# MIK32 register map
Vendor: Mikron; Series: MIK32; File version: 1.0
Registers are 32-bit, read-write, reset 0x0 unless marked. A register's access mark holds for its fields unless they carry their own. Offsets are from the block's base; [hi:lo] are bit positions.

## DAC0 — Управление ЦАП
Base 0x00085000
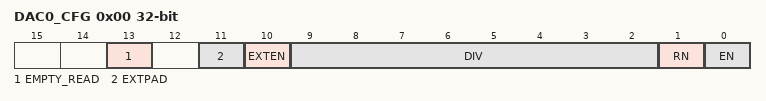
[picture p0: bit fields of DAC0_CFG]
0x00 DAC0_CFG — Регистр настойки ЦАП0
  [13] EMPTY_READ ro — Состояние входного регистра DAC_VALUE. Сбрасывается в 0 при записи нового значения в DAC_VALUE.
    0=Full (В DAC_VALUE находится необработанное значение); 1=Empty (Значение из DAC_VALUE передано в ЦАП, возможна запись следующего значения)
  [11] EXTPAD — Выбор источника внешнего опорного напряжения
    0=Calibrated_voltage_reference (Настраиваемый ИОН); 1=REF_DAC_PIN (Внешний вывод REF_ADC_DAC (PORT1_11))
  [10] EXTEN — Выбор источника опорного напряжения
    0=Internal (Встроенный); 1=External (Внешний)
  [9:2] DIV — Значение делителя тактового сигнала. Частота определяется как FЦАП=FIN/(DIV+1)
  [1] RN — Управление сбросом ЦАП, активный уровень «0»
  [0] EN — Управление питанием ЦАП
    0=Disable (Выключен); 1=Enable (Включен)
0x04 DAC0_VALUE — Входные данные для ЦАП0
  [11:0] VALUE — 12-разрядный входной код ЦАП

## DAC1 — Управление ЦАП
Base 0x00085008
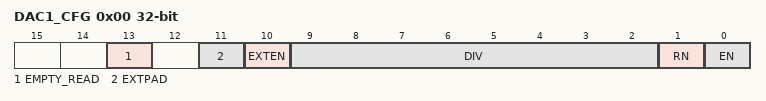
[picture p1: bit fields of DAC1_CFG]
0x00 DAC1_CFG — Регистр настойки ЦАП1
  [13] EMPTY_READ ro — Состояние входного регистра DAC_VALUE. Сбрасывается в 0 при записи нового значения в DAC_VALUE.
    0=Full (В DAC_VALUE находится необработанное значение); 1=Empty (Значение из DAC_VALUE передано в ЦАП, возможна запись следующего значения)
  [11] EXTPAD — Выбор источника внешнего опорного напряжения
    0=Calibrated_voltage_reference (Настраиваемый ИОН); 1=REF_DAC_PIN (Внешний вывод REF_ADC_DAC (PORT1_11))
  [10] EXTEN — Выбор источника опорного напряжения
    0=Internal (Встроенный); 1=External (Внешний)
  [9:2] DIV — Значение делителя тактового сигнала. Частота определяется как FЦАП=FIN/(DIV+1)
  [1] RN — Управление сбросом ЦАП, активный уровень «0»
  [0] EN — Управление питанием ЦАП
    0=Disable (Выключен); 1=Enable (Включен)
0x04 DAC1_VALUE — Входные данные для ЦАП1
  [11:0] VALUE — 12-разрядный входной код ЦАП

## TSENS — Управление температурным сенсором
Base 0x0008501C
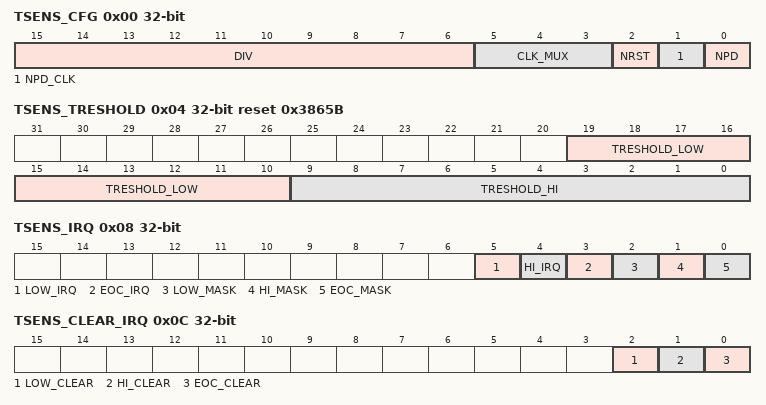
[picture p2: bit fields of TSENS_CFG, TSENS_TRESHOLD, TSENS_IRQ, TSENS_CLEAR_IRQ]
0x00 TSENS_CFG — Регистр настроек
  [15:6] DIV — Значение делителя тактового сигнала. Частота сенсора определяется как Tsens = Fin/(2*(Div + 1))
  [5:3] CLK_MUX — Выбор источника тактирования сенсора (Fin)
    0=Sys_clk (системная частота (sys_clk)); 1=HCLK (Частота шины AHB (hclk)); 2=OSC32M (Частота внешнего осциллятора 32 МГц); 3=HSI32M (Частота HSI32M); 4=OSC32K (Частота внешнего осциллятора 32 кГц); 5=LSI32K (Частота LSI32K)
  [2] NRST — Управление сбросом сенсора, активный уровень «0»
  [1] NPD_CLK — Управление тактированием сенсора
    0=Disable (Тактирование сенсора выключено); 1=Enable (Тактирование сенсора включено)
  [0] NPD — Управление питанием сенсора
    0=Disable (Сенсор выключен); 1=Enable (Сенсор включен)
0x04 TSENS_TRESHOLD reset 0x3865B — Регистр пороговых значений
  [19:10] TRESHOLD_LOW — При значении выхода сенсора менее LOW_THRESHOLD будет формироваться прерывание. Значение по умолчанию соответсвует температуре -40 оС
  [9:0] TRESHOLD_HI — При значении выхода сенсора больше HI_THRESHOLD будет формироваться прерывание. Значение по умолчанию соот-ветсвует температуре 125 оС
0x08 TSENS_IRQ — Регистр прерываний
  [5] LOW_IRQ ro — Статус прерывания события «выход сенсора меньше порогового значения LOW_ THRESHOLD»
  [4] HI_IRQ ro — Статус прерывания события «выход сенсора больше порогового значения HI_THRESHOLD»
  [3] EOC_IRQ ro — Статус прерывания по окончанию преобразования
  [2] LOW_MASK — Маска прерывания события «выход сенсора меньше порогового значения LOW_ THRESHOLD»
  [1] HI_MASK — Маска прерывания события «выход сенсора больше порогового значения HI_THRESHOLD»
  [0] EOC_MASK — Маска прерывания по окончанию преобразования
0x0C TSENS_CLEAR_IRQ wo write-1-clears — Регистр сброса прерываний
  [2] LOW_CLEAR write-1-clears — Сброс прерывания события «выход сенсора меньше порогового значения LOW_ THRESHOLD»
  [1] HI_CLEAR write-1-clears — Сброс прерывания события «выход сенсора больше порогового значения HI_THRESHOLD»
  [0] EOC_CLEAR write-1-clears — Сброс прерывания по окончанию преобразования
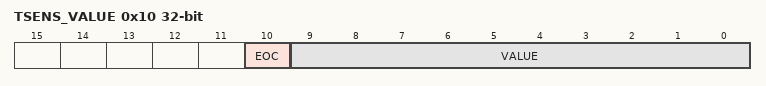
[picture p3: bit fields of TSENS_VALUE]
0x10 TSENS_VALUE ro — Регистр данных
  [10] EOC — Текущее значение выхода окончания преобразования
  [9:0] VALUE — Последнее измереннное значение сенсором
0x14 TSENS_SINGLE wo — Регистр запуска однократного измерения
  [0] SINGLE — Запуск одного измерения
0x18 TSENS_CONTINUOUS wo — Регистр запуска непрерываного измерения
  [0] CONTINUOUS — Запуск / остановка непрерывного измерения температуры

## REFV_CONFIG — Управление калибруемыми источниками напряжения и тока
Base 0x00085038
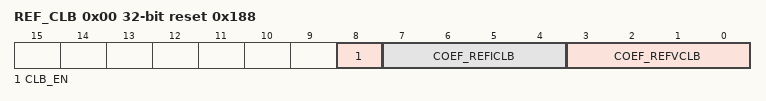
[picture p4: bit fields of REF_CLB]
0x00 REF_CLB reset 0x188 — Управление калибруемыми источниками тока и напряжения
  [8] CLB_EN — Разрешение работы калибруемых источников
    0=Disable (Калибруемые источники выключены); 1=Enable (Калибруемые источники включены)
  [7:4] COEF_REFICLB — Коэфициент настройки опорного источника тока
  [3:0] COEF_REFVCLB — Коэфициент настройки опорного источника напряжения

## ADC — Управление АЦП
Base 0x0008503C
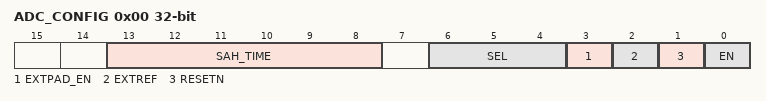
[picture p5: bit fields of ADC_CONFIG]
0x00 ADC_CONFIG — Регистр настойки
  [13:8] SAH_TIME — Время выборки очередного отсчета в тактах АЦП
  [6:4] SEL — Выбор канала АЦП
  [3] EXTPAD_EN — Выбор источника внешнего опорного напряжения
    0=Calibrated_voltage_reference (Настраиваемый ИОН); 1=REF_DAC_PIN (Внешний вывод REF_ADC_DAC (PORT1_11))
  [2] EXTREF — Выбор источника опорного напряжения
    0=Internal (Встроенный); 1=External (Внешний)
  [1] RESETN — Управление сбросом АЦП, активный уровень «0»
  [0] EN — Управление питанием АЦП
    0=Disable (Выключен); 1=Enable (Включен)
0x04 ADC_CONTINUOUS — Управление непрерывным измерением
  [0] CONTINUOUS — Запуск / остановка непрерывного измерения
0x08 ADC_SINGLE wo — Управление однократным измерением
  [0] SINGLE — Запуск однократного измерения
0x0C ADC_VALID ro — Регистр статуса
  [0] VALID — Признак наличия актуальных данных
0x10 ADC_VALUE ro — Регистр данных
  [11:0] VALUE — Результат преобразования

## SCR1_TIMER — Регистры системного таймера
Base 0x00490000
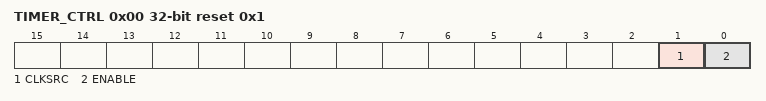
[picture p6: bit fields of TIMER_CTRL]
0x00 TIMER_CTRL reset 0x1 — Регистр конфигурации
  [1] CLKSRC — Источник тактрования системного таймера
    0=HCLK (Тактирование ядра (частота шины AHB hclk)); 1=External_clk (Внешний RTC (источник выбранный в PM.CPU_RTC_CLK_MUX))
  [0] ENABLE — Включение таймера
    0=Disable (Таймер выключен); 1=Enable (Таймер включен)
0x04 TIMER_DIV — Делитель частоты. Счет идет каждые DIV+1 такта частоты
  [9:0] DIV — Коэффициент деления частоты. Счет выполняется каждые DIV+1 тактов
0x08 MTIME — Счетчик таймера, младшее слово
0x0C MTIMEH — Счетчик таймера, старшее слово
0x10 MTIMECMP — Регистр сравнения, младшее слово
0x14 MTIMECMPH — Регистр сравнения, старшее слово
